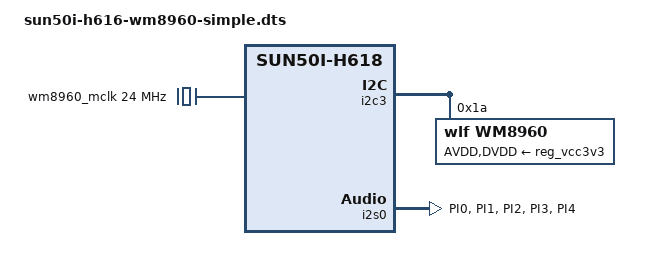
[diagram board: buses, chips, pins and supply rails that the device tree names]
/dts-v1/;
/plugin/;

/*
 * Alternative WM8960 overlay using mainline simple-audio-card + sun4i-i2s
 * For Orange Pi Zero 2W (Allwinner H618) with WM8960 Audio HAT
 * 
 * This approach uses the mainline I2S driver instead of vendor AHUB architecture
 * since the AHUB DAUDIO driver is not available in the kernel.
 */

/ {
	compatible = "xunlong,orangepi-zero2w", "allwinner,sun50i-h618";

	fragment@0 {
		target-path = "/";
		__overlay__ {
			/* Fixed 24MHz clock for WM8960 MCLK */
			wm8960_mclk: wm8960-mclk {
				compatible = "fixed-clock";
				#clock-cells = <0>;
				clock-frequency = <24000000>;
				clock-output-names = "wm8960-mclk";
			};
		};
	};

	fragment@1 {
		target = <&i2c3>;
		__overlay__ {
			#address-cells = <1>;
			#size-cells = <0>;

			wm8960: wm8960@1a {
				compatible = "wlf,wm8960";
				reg = <0x1a>;
				#sound-dai-cells = <0>;
				clocks = <&wm8960_mclk>;
				clock-names = "mclk";
				wlf,shared-lrclk;
				
				/* Dummy regulators for now */
				AVDD-supply = <&reg_vcc3v3>;
				DVDD-supply = <&reg_vcc3v3>;
			};
		};
	};

	fragment@2 {
		target = <&pio>;
		__overlay__ {
			/* I2S0 pins: BCLK, LRCK, DOUT, DIN on PI0-PI4 */
			i2s0_wm8960_pins: i2s0-wm8960-pins {
				pins = "PI0", "PI1", "PI2", "PI3", "PI4";
				function = "i2s0";
				drive-strength = <20>;
				bias-disable;
			};
		};
	};

	fragment@3 {
		target = <&i2s0>;
		__overlay__ {
			status = "okay";
			#sound-dai-cells = <0>;
			pinctrl-names = "default";
			pinctrl-0 = <&i2s0_wm8960_pins>;
		};
	};

	fragment@4 {
		target-path = "/";
		__overlay__ {
			sound {
				compatible = "simple-audio-card";
				simple-audio-card,name = "wm8960-audio";
				simple-audio-card,format = "i2s";
				simple-audio-card,mclk-fs = <256>;
				
				simple-audio-card,widgets =
					"Microphone", "Main Mic",
					"Line", "Line In",
					"Line", "Line Out",
					"Speaker", "Speaker",
					"Headphone", "Headphone Jack";
				
				simple-audio-card,routing =
					"Headphone Jack", "HP_L",
					"Headphone Jack", "HP_R",
					"Speaker", "SPK_LP",
					"Speaker", "SPK_LN",
					"Speaker", "SPK_RP",
					"Speaker", "SPK_RN",
					"LINPUT1", "Main Mic",
					"LINPUT3", "Main Mic",
					"RINPUT1", "Main Mic",
					"RINPUT2", "Main Mic";

				simple-audio-card,cpu {
					sound-dai = <&i2s0>;
					dai-tdm-slot-num = <2>;
					dai-tdm-slot-width = <32>;
				};

				simple-audio-card,codec {
					sound-dai = <&wm8960>;
					system-clock-frequency = <24000000>;
				};
			};
		};
	};
};
